VERSION "1.0"

NS_ :

BS_:

BU_: ECM BCM

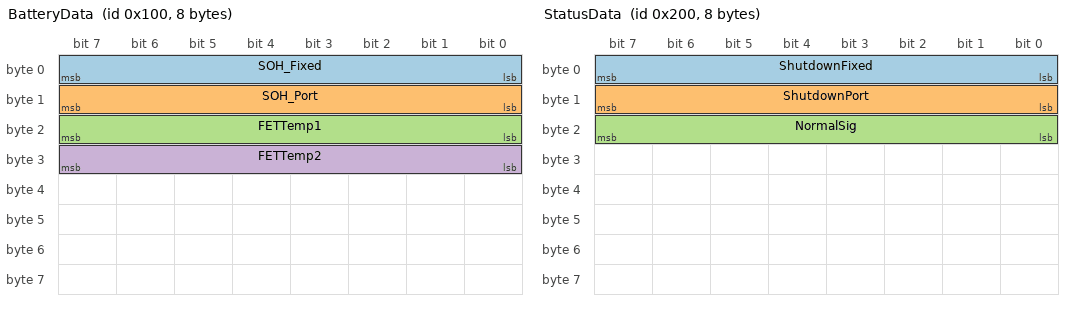
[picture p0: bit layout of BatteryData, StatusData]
BO_ 256 BatteryData : 8 ECM
 SG_ SOH_Fixed : 0|8@1+ (1,0) [0|100] "%" BCM
 SG_ SOH_Port : 8|8@1+ (1,0) [0|100] "%" BCM
 SG_ FETTemp1 : 16|8@1- (1,-40) [-40|215] "degC" BCM
 SG_ FETTemp2 : 24|8@1- (1,-40) [-40|215] "degC" BCM

BO_ 512 StatusData : 8 BCM
 SG_ ShutdownFixed : 0|8@1+ (1,0) [0|255] "" ECM
 SG_ ShutdownPort : 8|8@1+ (1,0) [0|255] "" ECM
 SG_ NormalSig : 16|8@1+ (1,0) [0|255] "" ECM

CM_ "General database comment
spanning two lines";

CM_ BO_ 256 "Battery data message
with multiline description
third line";

CM_ SG_ 256 SOH_Fixed "Portable battery - SOH";

CM_ SG_ 256 SOH_Port "Fixed battery - SOH
";

CM_ SG_ 256 FETTemp1 "Average temperature of fixed battery
";

CM_ SG_ 256 FETTemp2 "Average temperature of fixed battery
";

CM_ SG_ 512 ShutdownFixed "Portable battery shutdown status
along with time if needed";

CM_ SG_ 512 ShutdownPort "Fixed battery shutdown status";

CM_ SG_ 512 NormalSig "This is a normal single-line comment";

CM_ BO_ 512 "
";
